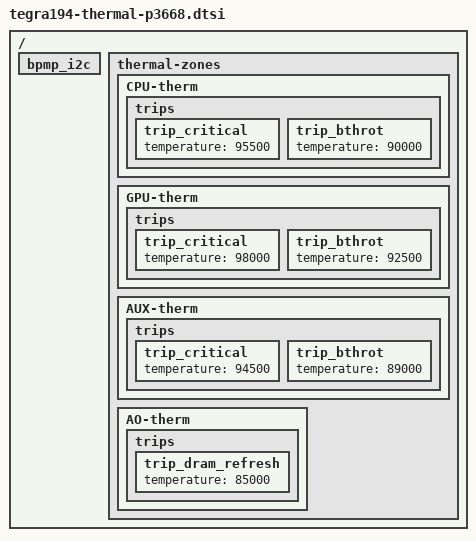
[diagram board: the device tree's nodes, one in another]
/*
 * Copyright (c) 2019, NVIDIA CORPORATION.  All rights reserved.
 *
 * This program is free software; you can redistribute it and/or modify
 * it under the terms of the GNU General Public License as published by
 * the Free Software Foundation; version 2 of the License.
 *
 * This program is distributed in the hope that it will be useful, but WITHOUT
 * ANY WARRANTY; without even the implied warranty of MERCHANTABILITY or
 * FITNESS FOR A PARTICULAR PURPOSE.  See the GNU General Public License for
 * more details.
 */

#include <t19x-common-platforms/tegra194-thermal.dtsi>
/ {
	bpmp_i2c {
		/delete-node/ temp-sensor@4c;
	};
	thermal-zones {
		/delete-node/ Tboard_tegra;
		/delete-node/ Tdiode_tegra;
		CPU-therm {
			trips {
				trip_critical {
					temperature = <95500>;
				};
				trip_bthrot {
					temperature = <90000>;
				};
			};
		};
		GPU-therm {
			trips {
				trip_critical {
					temperature = <98000>;
				};
				trip_bthrot {
					temperature = <92500>;
				};
			};
		};
		AUX-therm {
			trips {
				trip_critical {
					temperature = <94500>;
				};
				trip_bthrot {
					temperature = <89000>;
				};
			};
		};
		AO-therm {
			trips {
				trip_dram_refresh {
					temperature = <85000>;
				};
			};
		};
	};
};
